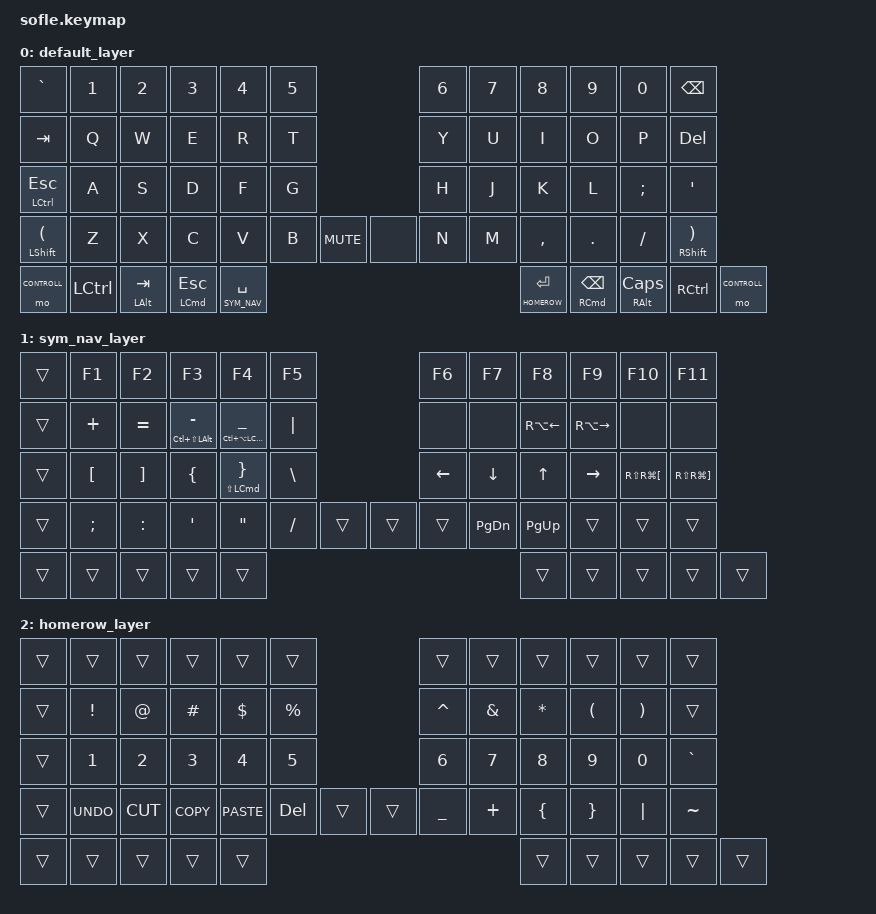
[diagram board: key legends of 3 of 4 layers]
/*
 * Copyright (c) 2020 The ZMK Contributors
 *
 * SPDX-License-Identifier: MIT
 */


#include <behaviors.dtsi>
#include <dt-bindings/zmk/bt.h>
#include <dt-bindings/zmk/ext_power.h>
#include <dt-bindings/zmk/keys.h>
#include <dt-bindings/zmk/outputs.h>
#include <dt-bindings/zmk/rgb.h>
#define DEFAULT 0
#define SYM_NAV 1
#define HOMEROW 2
#define CONTROLL 3

&caps_word {
    continue-list = <UNDERSCORE MINUS>;
};

&led_strip {
    chain-length = <35>;
};

&left_encoder {
    resolution = <2>;
};


/ {
    keymap {
        compatible = "zmk,keymap";

        default_layer {
            bindings = <
                &kp GRAVE  &kp N1  &kp N2  &kp N3  &kp N4  &kp N5                       &kp N6  &kp N7  &kp N8  &kp N9  &kp N0  &kp BSPC
                &kp TAB    &kp Q   &kp W   &kp E   &kp R   &kp T                        &kp Y   &kp U   &kp I   &kp O   &kp P   &kp DEL
                &mt LCTRL ESC &kp A &kp S  &kp D   &kp F   &kp G                        &kp H   &kp J   &kp K   &kp L   &kp SEMI &kp SQT
                &mt LSHFT LPAR &kp Z &kp X &kp C   &kp V   &kp B   &kp C_MUTE &none     &kp N   &kp M   &kp COMMA &kp DOT &kp FSLH &mt RSHFT RPAR
                    &mo CONTROLL &kp LCTRL &mt LALT TAB &mt LCMD ESC &lt SYM_NAV SPACE &lt HOMEROW RET &mt RCMD BSPC &mt RALT CAPS &kp RCTRL &mo CONTROLL
            >;
            sensor-bindings = <&inc_dec_kp C_VOL_UP C_VOL_DN &inc_dec_kp PG_UP PG_DN>;
        };

        sym_nav_layer {
            bindings = <
                &trans  &kp F1  &kp F2  &kp F3  &kp F4  &kp F5                                                              &kp F6  &kp F7  &kp F8  &kp F9  &kp F10 &kp F11
                &trans  &kp PLUS	&kp EQUAL	&mt LC(LS(LALT)) MINUS	&mt LC(LA(LCMD)) UNDER	&kp PIPE                    &none		&none		&kp RA(LEFT)	&kp RA(RIGHT)	&none   &none
                &trans  &kp LBKT	&kp RBKT	&kp LBRC				&mt LS(LCMD) RBRC		&kp BSLH                    &kp LEFT	&kp DOWN	&kp UP			&kp RIGHT		&kp RS(RG(LBKT))	&kp RS(RG(RBKT))
                &trans  &kp SEMI	&kp COLON	&kp SQT					&kp DQT					&kp FSLH  &trans  &trans    &trans		&kp PG_DN	&kp PG_UP		&trans			&trans				&trans
                    &trans  &trans  &trans  &trans  &trans  &trans    &trans  &trans  &trans  &trans
            >;
            sensor-bindings = <&inc_dec_kp C_VOL_UP C_VOL_DN &inc_dec_kp PG_UP PG_DN>;
        };

        homerow_layer {
            bindings = <
                &trans  &trans  &trans  &trans  &trans  &trans                                  &trans  &trans  &trans  &trans  &trans  &trans
                &trans  &kp EXCL &kp AT &kp HASH &kp DLLR &kp PRCNT                             &kp CARET &kp AMPS &kp ASTRK &kp LPAR &kp RPAR &trans
                &trans  &kp N1  &kp N2  &kp N3  &kp N4  &kp N5                                  &kp N6  &kp N7  &kp N8  &kp N9  &kp N0  &kp GRAVE
                &trans  &kp K_UNDO &kp K_CUT &kp K_COPY &kp K_PASTE &kp DEL  &trans  &trans     &kp UNDER &kp PLUS &kp LBRC &kp RBRC &kp PIPE &kp TILDE
                    &trans  &trans  &trans  &trans  &trans  &trans    &trans  &trans  &trans  &trans
            >;
            sensor-bindings = <&inc_dec_kp C_VOL_UP C_VOL_DN &inc_dec_kp PG_UP PG_DN>;
        };

        control_layer {
            bindings = <
                &trans  &trans  &trans  &trans  &trans  &trans                &trans  &trans  &trans  &trans  &trans  &trans
                &trans  &bt BT_CLR &bt BT_SEL 0 &bt BT_SEL 1 &bt BT_SEL 2 &bt BT_SEL 3    &trans  &trans  &trans  &trans  &trans  &trans
                &trans  &rgb_ug RGB_TOG &rgb_ug RGB_HUI &rgb_ug RGB_SAI &rgb_ug RGB_BRI &trans    &trans  &trans  &trans  &trans  &trans  &trans
                &trans  &rgb_ug RGB_EFF &rgb_ug RGB_HUD &rgb_ug RGB_SAD &rgb_ug RGB_BRD &bootloader &trans    &trans  &trans  &trans  &trans  &trans  &trans
                    &trans  &trans  &trans  &trans  &trans  &trans    &trans  &trans  &trans  &trans
            >;
            sensor-bindings = <&inc_dec_kp C_VOL_UP C_VOL_DN &inc_dec_kp PG_UP PG_DN>;
        };
    };
};
